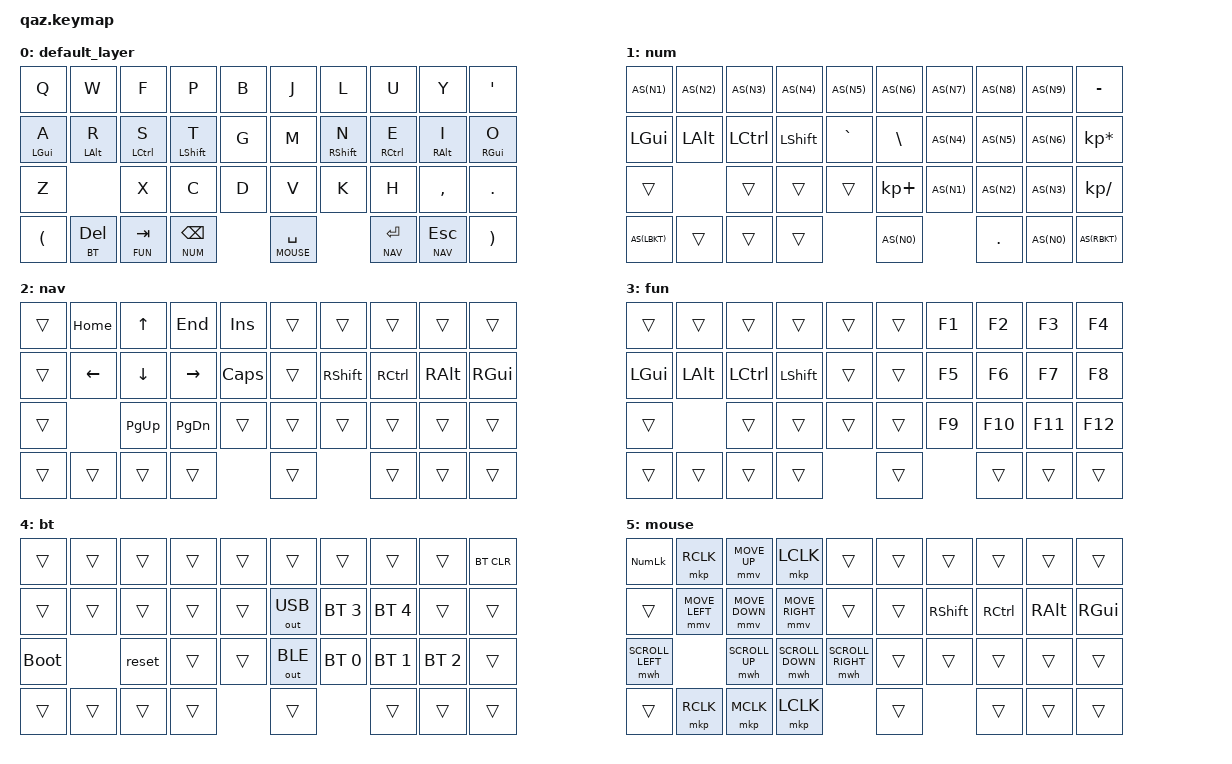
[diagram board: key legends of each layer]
/*
 * Copyright (c) 2020 The ZMK Contributors
 *
 * SPDX-License-Identifier: MIT
 */
/*
 * Copyright (c) 2020 The ZMK Contributors
 *
 * SPDX-License-Identifier: MIT
 */

#include <behaviors.dtsi>
#include <dt-bindings/zmk/keys.h>
#include <dt-bindings/zmk/bt.h>
#include <dt-bindings/zmk/outputs.h>
#include <dt-bindings/zmk/mouse.h>

#define DEFAULT 0
#define NUM     1
#define NAV     2
#define FUN     3
#define BT      4
#define MOUSE   5

#define AS(keycode) &as LS(keycode) keycode

&lt { quick_tap_ms = <140>; };

/ {
    behaviors {
        hm: homerow_mods {
            compatible = "zmk,behavior-hold-tap";
            label = "homerow mods";
            #binding-cells = <2>;
            tapping-term-ms = <180>;
            quick-tap-ms = <140>;
            flavor = "tap-preferred";
            bindings = <&kp>, <&kp>;
        };
        
        as: auto_shift {
            compatible = "zmk,behavior-hold-tap";
            label = "AUTO_SHIFT";
            #binding-cells = <2>;
            tapping_term_ms = <180>;
            quick_tap_ms = <0>;
            flavor = "tap-preferred";
            bindings = <&kp>, <&kp>;
        };        
    };
};

/ {
    combos {
        compatible = "zmk,combos";
        combo_esc {
            timeout-ms = <25>;
            key-positions = <3 4>;
            bindings = <&kp ESC>;
        };
        
        
       combo_minus {
            timeout-ms = <25>;
            key-positions = <2 3>;
            bindings = <&kp MINUS>;
        };
        
        combo_equal {
            timeout-ms = <25>;
            key-positions = <6 7>;
            bindings = <&kp EQUAL>;
        };
        
        combo_bspace {
            timeout-ms = <25>;
            key-positions = <5 6>;
            bindings = <&kp BSPC>;
        };        
 /*       
        combo_tab {
            timeout-ms = <25>;
            key-positions = <10 11>;
            bindings = <&kp TAB>;
        }; 
        
        combo_quote {
            timeout-ms = <25>;
            key-positions = <10 19>;
            bindings = <&kp SQT>;
        };         
 */      
        combo_caps {
            timeout-ms = <25>;
            key-positions = <13 14>;
            bindings = <&caps_word>;
        };
        
        combo_num {
            timeout-ms = <25>;
            key-positions = <21 22 23>;
            bindings = <&kp KP_NUM>;
        };
        
        combo_capslock {
            timeout-ms = <25>;
            key-positions = <23 24 25>;
            bindings = <&kp CAPS>;
        };
        
        combo_scroll {
            timeout-ms = <25>;
            key-positions = <25 26 27>;
            bindings = <&kp SLCK>;
        };
        
        combo_semi {
            timeout-ms = <25>;
            key-positions = <15 16>;
            bindings = <&kp SEMI>;
        }; 
        
        combo_slash {
            timeout-ms = <25>;
            key-positions = <27 28>;
            bindings = <&kp FSLH>;
        };  
        
        combo_print {
            timeout-ms = <25>;
            key-positions = <0 9>;
            bindings = <&kp PSCRN>;
        };
        
        combo_mute {
            timeout-ms = <25>;
            key-positions = <9 36>;
            bindings = <&kp C_MUTE>;
        };
        
        combo_pause {
            timeout-ms = <25>;
            key-positions = <0 29>;
            bindings = <&kp C_PP>;
        };
        
   };
};

/ {
    keymap {
        compatible = "zmk,keymap";
           default_layer {
            bindings = <
    &kp Q      &kp W        &kp F       &kp P       &kp B  &kp J  &kp L       &kp U       &kp Y       &kp SQT
    &hm LGUI A &hm LALT R   &hm LCTRL S &hm LSHFT T &kp G  &kp M  &hm RSHFT N &hm RCTRL E &hm RALT I  &hm RGUI O
    &kp Z                   &kp X       &kp C       &kp D  &kp V  &kp K       &kp H       &kp COMMA   &kp DOT
    &kp LPAR   &lt BT DEL   &lt FUN TAB &lt NUM BSPC       &lt MOUSE SPACE    &lt NAV RET &lt NAV ESC &kp RPAR
            >;
        };
        num {
            bindings = <
    AS(N1)     AS(N2)     AS(N3)     AS(N4)      AS(N5)    AS(N6)      AS(N7)      AS(N8)      AS(N9)    &kp MINUS
    &kp LGUI   &kp LALT   &kp LCTRL  &kp LSHFT   &kp GRAVE &kp BSLH    AS(N4)      AS(N5)      AS(N6)    &kp KP_MULTIPLY
    &trans                &trans     &trans      &trans    &kp KP_PLUS AS(N1)      AS(N2)      AS(N3)    &kp KP_DIVIDE
    AS(LBKT)   &trans     &trans     &trans              AS(N0)                    &kp DOT     AS(N0)    AS(RBKT)
            >;
        };

        nav {
            bindings = <
    &trans  &kp HOME   &kp UP     &kp END     &kp INS  &trans   &trans    &trans      &trans      &trans
    &trans  &kp LEFT   &kp DOWN   &kp RIGHT   &kp CAPS &trans   &kp RSHFT &kp RCTRL   &kp RALT    &kp RGUI
    &trans             &kp PG_UP  &kp PG_DN   &trans   &trans   &trans    &trans      &trans      &trans      
    &trans  &trans     &trans     &trans               &trans             &trans      &trans      &trans
            >;
        };
        
        fun {
            bindings = <
    &trans     &trans     &trans     &trans      &trans &trans &kp F1      &kp F2      &kp F3    &kp F4 
    &kp LGUI   &kp LALT   &kp LCTRL  &kp LSHFT   &trans &trans &kp F5      &kp F6      &kp F7    &kp F8 
    &trans                &trans     &trans      &trans &trans &kp F9      &kp F10     &kp F11   &kp F12
    &trans     &trans     &trans     &trans             &trans             &trans      &trans    &trans
            >;
        };   
        
        bt {
            bindings = <
    &trans     &trans     &trans     &trans      &trans &trans       &trans       &trans       &trans       &bt BT_CLR
    &trans     &trans     &trans     &trans      &trans &out OUT_USB &bt BT_SEL 3 &bt BT_SEL 4 &trans       &trans
    &bootloader           &reset     &trans      &trans &out OUT_BLE &bt BT_SEL 0 &bt BT_SEL 1 &bt BT_SEL 2 &trans      
    &trans     &trans     &trans     &trans             &trans                &trans       &trans       &trans
            >;
        }; 
        
        mouse {
            bindings = <                     
    &kp KP_NUM       &mkp RCLK        &mmv MOVE_UP      &mkp LCLK         &trans   &trans   &trans    &trans      &trans      &trans
    &trans           &mmv MOVE_LEFT   &mmv MOVE_DOWN    &mmv MOVE_RIGHT   &trans   &trans   &kp RSHFT &kp RCTRL   &kp RALT    &kp RGUI
    &mwh SCROLL_LEFT &mwh SCROLL_UP   &mwh SCROLL_DOWN  &mwh SCROLL_RIGHT &trans   &trans   &trans   &trans    &trans
    &trans     &mkp RCLK              &mkp MCLK         &mkp LCLK         &trans            &trans   &trans    &trans
            >;         
        };              
    };
};


/*
/ {
    keymap {
        compatible = "zmk,keymap";

        default_layer {
            bindings = <
    &kp Q      &kp W        &kp E       &kp R       &kp T  &kp Y  &kp U       &kp I       &kp O       &kp P
    &hm LGUI A &hm LALT S   &hm LCTRL D &hm LSHFT F &kp G  &kp H  &hm RSHFT J &hm RCTRL K &hm RALT L  &hm RGUI RET
    &kp Z                   &kp X       &kp C       &kp V  &kp B  &kp N       &kp M       &kp COMMA   &kp DOT
    &lt BT LPAR &lt FUN DEL &kp LALT    &lt NAV BSPC       &lt NUM SPACE      &kp SEMI    &lt NAV TAB &lt BT RPAR
            >;
        };
        
        default_layer {
            bindings = <
    &kp Q      &kp W        &kp F       &kp P       &kp B  &kp J  &kp L       &kp U       &kp Y       &kp SQT
    &hm LGUI A &hm LALT R   &hm LCTRL S &hm LSHFT T &kp G  &kp M  &hm RSHFT N &hm RCTRL E &hm RALT I  &hm RGUI O
    &kp Z                   &kp X       &kp C       &kp D  &kp V  &kp K       &kp H       &kp COMMA   &kp DOT
    &kp LPAR   &lt BT DEL   &lt FUN TAB &lt NUM BSPC       &lt MOUSE SPACE    &lt NAV RET &lt NAV ESC &kp RPAR
            >;
        };
*/
